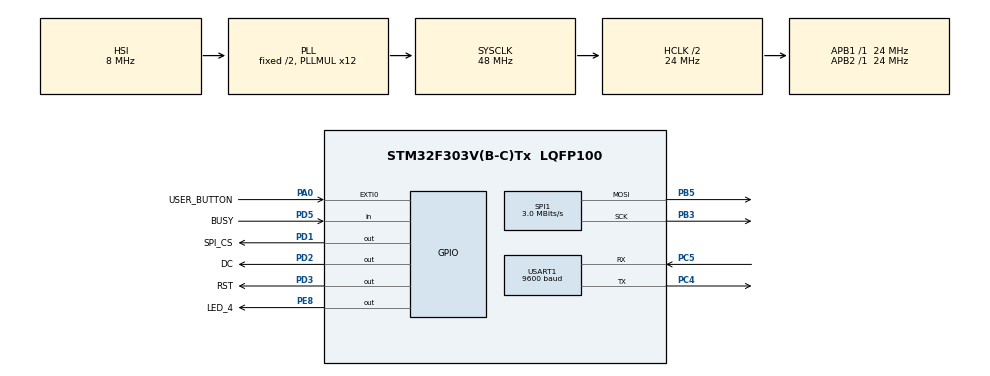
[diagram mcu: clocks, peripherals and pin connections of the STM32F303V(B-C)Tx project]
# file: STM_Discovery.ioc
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Mcu.Family=STM32F3
Mcu.Name=STM32F303V(B-C)Tx
Mcu.Package=LQFP100
NVIC.EXTI0_IRQn=true\:1\:0\:true\:false\:true\:true\:true
NVIC.PriorityGroup=NVIC_PRIORITYGROUP_4
NVIC.USART1_IRQn=true\:1\:0\:true\:false\:true\:true\:true
PA0.GPIO_Label=USER_BUTTON
PA0.Signal=GPXTI0
PA13.Mode=Serial_Wire
PA13.Signal=SYS_JTMS-SWDIO
PA14.Mode=Serial_Wire
PA14.Signal=SYS_JTCK-SWCLK
PB3.Mode=TX_Only_Simplex_Unidirect_Master
PB3.Signal=SPI1_SCK
PB5.Mode=TX_Only_Simplex_Unidirect_Master
PB5.Signal=SPI1_MOSI
PC4.Mode=Asynchronous
PC4.Signal=USART1_TX
PC5.Mode=Asynchronous
PC5.Signal=USART1_RX
PD1.GPIO_Label=SPI_CS
PD1.Signal=GPIO_Output
PD2.GPIO_Label=DC
PD2.Signal=GPIO_Output
PD3.GPIO_Label=RST
PD3.Signal=GPIO_Output
PD5.GPIO_Label=BUSY
PD5.Signal=GPIO_Input
PE8.GPIO_Label=LED_4
PE8.Signal=GPIO_Output
ProjectManager.HeapSize=0x200
ProjectManager.StackSize=0x400
ProjectManager.TargetToolchain=STM32CubeIDE
RCC.AHBCLKDivider=RCC_SYSCLK_DIV2
RCC.AHBFreq_Value=24000000
RCC.APB1Freq_Value=24000000
RCC.APB1TimFreq_Value=24000000
RCC.APB2Freq_Value=24000000
RCC.APB2TimFreq_Value=24000000
RCC.CortexFreq_Value=24000000
RCC.HCLKFreq_Value=24000000
RCC.HSE_VALUE=8000000
RCC.HSI_VALUE=8000000
RCC.LSE_VALUE=32768
RCC.PLLMUL=RCC_PLL_MUL12
RCC.SYSCLKFreq_VALUE=48000000
RCC.SYSCLKSourceVirtual=RCC_SYSCLKSOURCE_PLLCLK
RCC.USBFreq_Value=48000000
SPI1.BaudRatePrescaler=SPI_BAUDRATEPRESCALER_8
SPI1.CalculateBaudRate=3.0 MBits/s
SPI1.DataSize=SPI_DATASIZE_8BIT
SPI1.Direction=SPI_DIRECTION_2LINES
SPI1.Mode=SPI_MODE_MASTER
SPI1.VirtualType=VM_MASTER
USART1.BaudRate=9600
USART1.VirtualMode-Asynchronous=VM_ASYNC
board=STM32F3DISCOVERY

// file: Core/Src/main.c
/* USER CODE BEGIN Header */
/**
  ******************************************************************************
  * @file           : main.c
  * @brief          : Main program body
  ******************************************************************************
  * @attention
  *
  * <h2><center>&copy; Copyright (c) 2020 STMicroelectronics.
  * All rights reserved.</center></h2>
  *
  * This software component is licensed by ST under BSD 3-Clause license,
  * the "License"; You may not use this file except in compliance with the
  * License. You may obtain a copy of the License at:
  *                        opensource.org/licenses/BSD-3-Clause
  *
  ******************************************************************************
  */
/* USER CODE END Header */

#include "main.h"
#include "spi.h"
#include "usart.h"
#include "gpio.h"

/* USER CODE BEGIN Includes */
#include "../../PeripheralDrivers/Display/EPD_Test.h"
#include "EPD_2in13bc.h"

/* USER CODE END Includes */

void SystemClock_Config(void);

int main(void)
{

  /* MCU Configuration--------------------------------------------------------*/

  /* Reset of all peripherals, Initializes the Flash interface and the Systick. */
   HAL_Init();

  /* Configure the system clock */
  SystemClock_Config();

  /* Initialize all configured peripherals */
  MX_GPIO_Init();
  MX_SPI1_Init();
  MX_USART1_UART_Init();
  /* USER CODE BEGIN 2 */
  //EPD_2in13_V2_test();
  EPD_2in13bc_test();
  //UserInit();

  /* USER CODE END 2 */

  /* Infinite loop */
  while (1)
  {

  }
}

void SystemClock_Config(void)
{
  RCC_OscInitTypeDef RCC_OscInitStruct = {0};
  RCC_ClkInitTypeDef RCC_ClkInitStruct = {0};
  RCC_PeriphCLKInitTypeDef PeriphClkInit = {0};

  /** Initializes the CPU, AHB and APB busses clocks
  */
  RCC_OscInitStruct.OscillatorType = RCC_OSCILLATORTYPE_HSI;
  RCC_OscInitStruct.HSIState = RCC_HSI_ON;
  RCC_OscInitStruct.HSICalibrationValue = RCC_HSICALIBRATION_DEFAULT;
  RCC_OscInitStruct.PLL.PLLState = RCC_PLL_ON;
  RCC_OscInitStruct.PLL.PLLSource = RCC_PLLSOURCE_HSI;
  RCC_OscInitStruct.PLL.PLLMUL = RCC_PLL_MUL12;
  if (HAL_RCC_OscConfig(&RCC_OscInitStruct) != HAL_OK)
  {
    Error_Handler();
  }
  /** Initializes the CPU, AHB and APB busses clocks
  */
  RCC_ClkInitStruct.ClockType = RCC_CLOCKTYPE_HCLK|RCC_CLOCKTYPE_SYSCLK
                              |RCC_CLOCKTYPE_PCLK1|RCC_CLOCKTYPE_PCLK2;
  RCC_ClkInitStruct.SYSCLKSource = RCC_SYSCLKSOURCE_PLLCLK;
  RCC_ClkInitStruct.AHBCLKDivider = RCC_SYSCLK_DIV2;
  RCC_ClkInitStruct.APB1CLKDivider = RCC_HCLK_DIV1;
  RCC_ClkInitStruct.APB2CLKDivider = RCC_HCLK_DIV1;

  if (HAL_RCC_ClockConfig(&RCC_ClkInitStruct, FLASH_LATENCY_0) != HAL_OK)
  {
    Error_Handler();
  }
  PeriphClkInit.PeriphClockSelection = RCC_PERIPHCLK_USART1;
  PeriphClkInit.Usart1ClockSelection = RCC_USART1CLKSOURCE_PCLK2;
  if (HAL_RCCEx_PeriphCLKConfig(&PeriphClkInit) != HAL_OK)
  {
    Error_Handler();
  }
}

void Error_Handler(void)
{
}

/************************ (C) COPYRIGHT STMicroelectronics *****END OF FILE****/
